AUTOSAR XML (schema 4-2-2)
package /Components
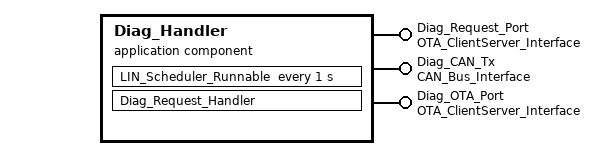
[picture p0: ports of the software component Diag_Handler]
  application sw component type Diag_Handler
    provide port Diag_Request_Port: provided-interface=OTA_ClientServer_Interface
    provide port Diag_CAN_Tx: provided-interface=CAN_Bus_Interface
    provide port Diag_OTA_Port: provided-interface=OTA_ClientServer_Interface
    provide/require port CanTransport_Client: provided-required-interface=CAN_Bus_Interface
    provide/require port LinTransport_Client: provided-required-interface=LIN_Bus_Interface
    provide/require port OTA_Client: provided-required-interface=OTA_ClientServer_Interface
    behavior Diag_Handler_InternalBehavior
      operation invoked event Diagnostic_Request_Received: start-on-event=CAN_Rx_Dispatch_Runnable, operation=Diag_Request_Port.DiagnosticRequest
      timing event OTA_Timeout_Check: start-on-event=LIN_Scheduler_Runnable, period=1
      runnable Diag_Request_Handler: minimum-start-interval=1000, symbol=Diag_Handler_Diag_Request_Handler
        data-send-points:
          access Diag_To_CAN: accessed-variable=Diag_CAN_Tx.Diag_Frame
          access OTA_Segment_Out: accessed-variable=Diag_OTA_Port.FW_Segment
        sync call Call_CAN_Transmit: called-from-within-exclusive-area=EA1, operation=CanTransport_Client.TransmitFrame, timeout=200
        sync call Call_LIN_Transmit: called-from-within-exclusive-area=EA1, operation=LinTransport_Client.TransmitFrame, timeout=500
        sync call Call_OTA_Transport: called-from-within-exclusive-area=EA1, operation=OTA_Client.OTA_Transport, timeout=30000
